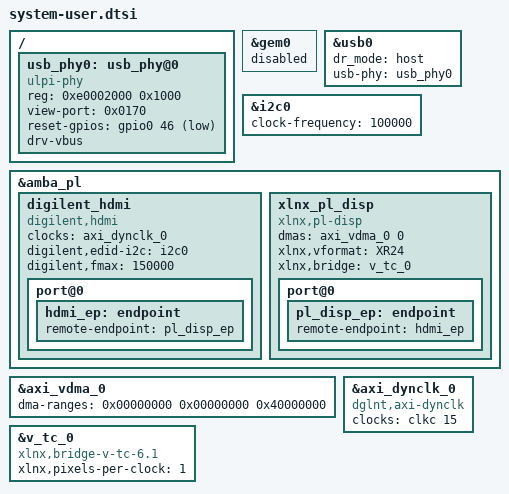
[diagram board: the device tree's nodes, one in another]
/include/ "system-conf.dtsi"
/ {
};
/ {


	usb_phy0: usb_phy@0 {
		compatible = "ulpi-phy";
		#phy-cells = <0>;
		reg = <0xe0002000 0x1000>;
		view-port = <0x0170>;
		reset-gpios = <&gpio0 46 1>;
		drv-vbus;
	};
};

&gem0 {
    status = "disabled";
};


&usb0 {
	status = "okay";
	dr_mode = "host";
	usb-phy = <&usb_phy0>;
};

&i2c0 {
	clock-frequency = <100000>;
	status = "okay";
};

&amba_pl {
	digilent_hdmi {
		compatible = "digilent,hdmi";
		clocks = <&axi_dynclk_0>;
		clock-names = "clk";
		digilent,edid-i2c = <&i2c0>;
		digilent,fmax = <150000>;

		port@0 {
			hdmi_ep: endpoint {
				remote-endpoint = <&pl_disp_ep>;
			};
		};
	};

	xlnx_pl_disp {
		compatible = "xlnx,pl-disp";
		dmas = <&axi_vdma_0 0>;
		dma-names = "dma0";
		xlnx,vformat = "XR24";
		xlnx,bridge = <&v_tc_0>;

		port@0 {
			pl_disp_ep: endpoint {
				remote-endpoint = <&hdmi_ep>;
			};
		};
	};
};

&axi_vdma_0 {
	dma-ranges = <0x00000000 0x00000000 0x40000000>;
};

&axi_dynclk_0 {
	compatible = "dglnt,axi-dynclk";
	#clock-cells = <0>;
	clocks = <&clkc 15>;
};

&v_tc_0 {
	compatible = "xlnx,bridge-v-tc-6.1";
	xlnx,pixels-per-clock = <1>;
};

